# iostr735 register map
Registers are 16-bit, access not given, no defined reset value unless marked. A register's access mark holds for its fields unless they carry their own. Addresses are absolute; registers are grouped by the start of their names; [hi:lo] are bit positions; {n}, {i} and the like mark numbered series.

## GPIOPORT4
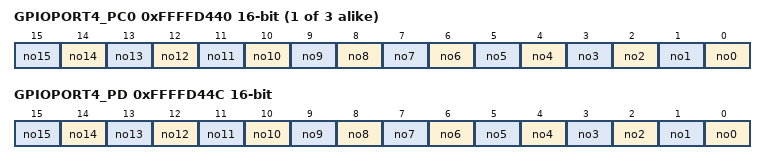
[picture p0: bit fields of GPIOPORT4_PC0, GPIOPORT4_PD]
{0xFFFFD440+4i} GPIOPORT4_PC{i} (i=0..2)
  [n] no{n} (n=0..15)
0xFFFFD44C GPIOPORT4_PD
  [n] no{n} (n=0..15)

## GPIOPORT5
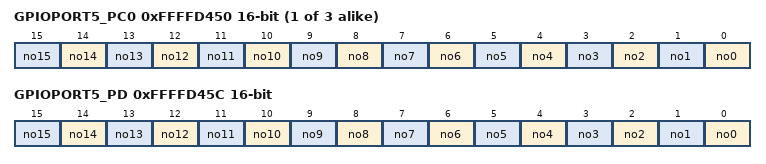
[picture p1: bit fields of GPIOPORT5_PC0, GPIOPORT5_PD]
{0xFFFFD450+4i} GPIOPORT5_PC{i} (i=0..2)
  [n] no{n} (n=0..15)
0xFFFFD45C GPIOPORT5_PD
  [n] no{n} (n=0..15)

## GPIOPORT6
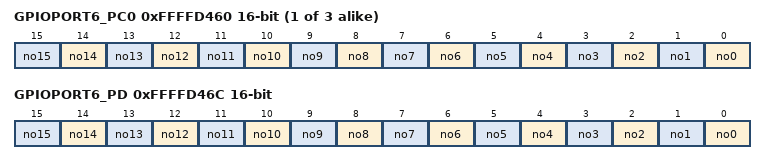
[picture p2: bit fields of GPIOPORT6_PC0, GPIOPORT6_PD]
{0xFFFFD460+4i} GPIOPORT6_PC{i} (i=0..2)
  [n] no{n} (n=0..15)
0xFFFFD46C GPIOPORT6_PD
  [n] no{n} (n=0..15)

## EIC
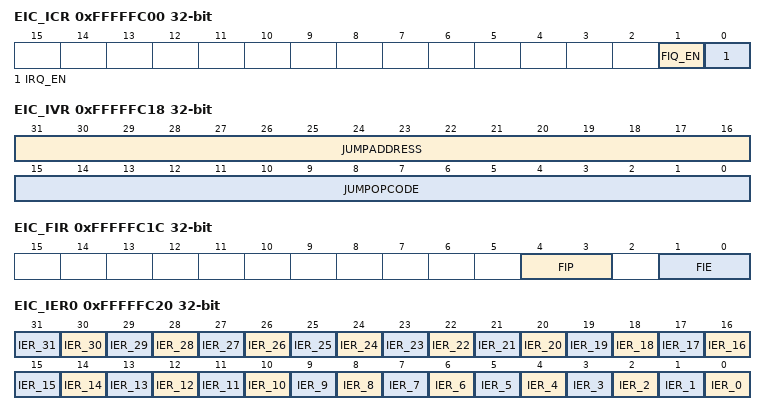
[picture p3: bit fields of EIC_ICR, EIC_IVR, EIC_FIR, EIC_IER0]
0xFFFFFC00 EIC_ICR 32-bit
  [1] FIQ_EN, [0] IRQ_EN
0xFFFFFC04 EIC_CICR 32-bit
  [5:0] CIC
0xFFFFFC08 EIC_CIPR 32-bit
  [3:0] CIP
0xFFFFFC10 EIC_FIER 32-bit
  [1:0] FIE
0xFFFFFC14 EIC_FIPR 32-bit
  [1:0] FIP
0xFFFFFC18 EIC_IVR 32-bit
  [31:16] JUMPADDRESS, [15:0] JUMPOPCODE
0xFFFFFC1C EIC_FIR 32-bit
  [4:3] FIP, [1:0] FIE
0xFFFFFC20 EIC_IER0 32-bit
  [n] IER_{n} (n=0..31)
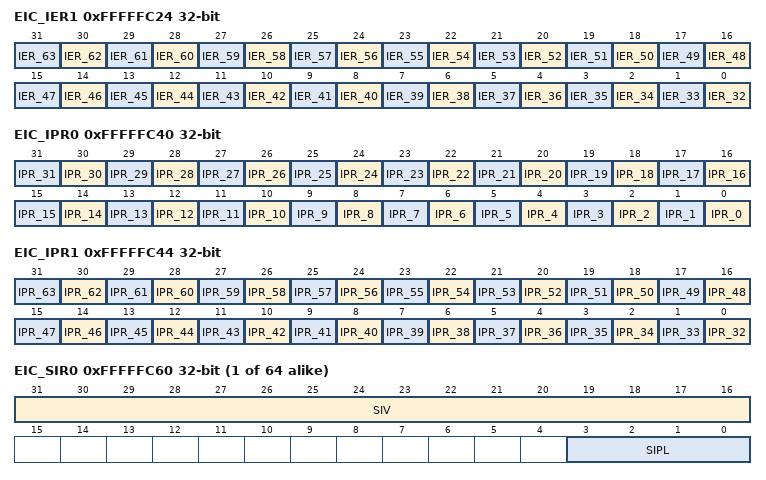
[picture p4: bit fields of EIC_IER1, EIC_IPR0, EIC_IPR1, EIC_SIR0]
0xFFFFFC24 EIC_IER1 32-bit
  [n-32] IER_{n} (n=32..63)
0xFFFFFC40 EIC_IPR0 32-bit
  [n] IPR_{n} (n=0..31)
0xFFFFFC44 EIC_IPR1 32-bit
  [n-32] IPR_{n} (n=32..63)
{0xFFFFFC60+4i} EIC_SIR{i} 32-bit (i=0..63)
  [31:16] SIV, [3:0] SIPL

## ARB
0x20000000 ARB_TOR 32-bit
  [15:0] TIMEOUT
0x20000004 ARB_PRIOR 32-bit
  [1:0] PRIORITY
0x2000000C ARB_CTRL 32-bit
  [1] ABORT

## FLASH
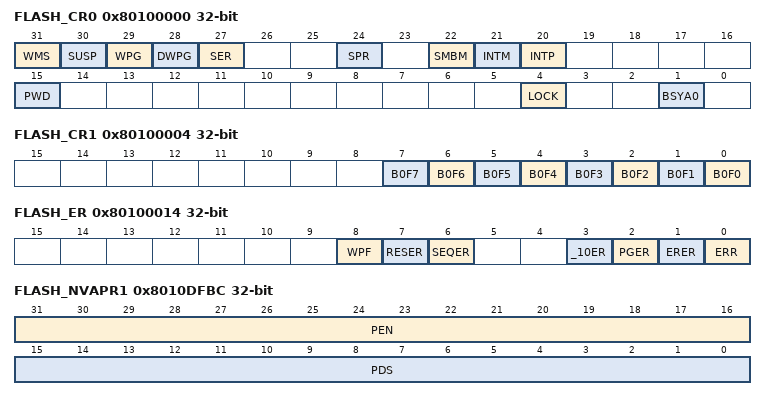
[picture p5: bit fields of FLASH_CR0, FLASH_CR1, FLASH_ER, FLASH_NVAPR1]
0x80100000 FLASH_CR0 32-bit
  [31] WMS, [30] SUSP, [29] WPG, [28] DWPG, [27] SER, [24] SPR, [22] SMBM, [21] INTM, [20] INTP, [15] PWD, [4] LOCK, [1] BSYA0
0x80100004 FLASH_CR1 32-bit
  [n] B0F{n} (n=0..7)
0x80100008 FLASH_DR0 32-bit
0x8010000C FLASH_DR1 32-bit
0x80100010 FLASH_AR 32-bit
  [20:0] ADD
0x80100014 FLASH_ER 32-bit
  [8] WPF, [7] RESER, [6] SEQER, [3] _10ER, [2] PGER, [1] ERER, [0] ERR
0x8010DFB0 FLASH_NVWPAR 32-bit
  [7:0] W0P
0x8010DFB8 FLASH_NVAPR0 32-bit
  [1] DBGP
0x8010DFBC FLASH_NVAPR1 32-bit
  [31:16] PEN, [15:0] PDS

## APB0
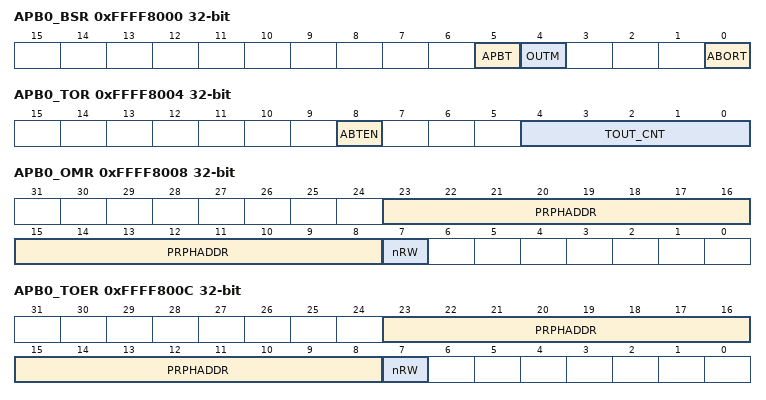
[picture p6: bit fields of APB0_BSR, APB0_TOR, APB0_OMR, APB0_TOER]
0xFFFF8000 APB0_BSR 32-bit
  [5] APBT, [4] OUTM, [0] ABORT
0xFFFF8004 APB0_TOR 32-bit
  [8] ABTEN, [4:0] TOUT_CNT
0xFFFF8008 APB0_OMR 32-bit
  [23:8] PRPHADDR, [7] nRW
0xFFFF800C APB0_TOER 32-bit
  [23:8] PRPHADDR, [7] nRW

## I2C0
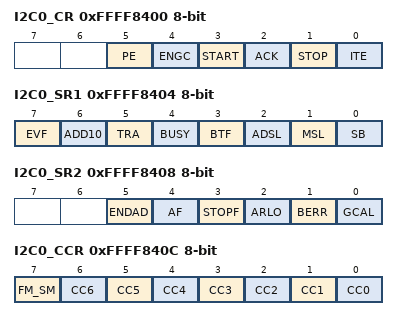
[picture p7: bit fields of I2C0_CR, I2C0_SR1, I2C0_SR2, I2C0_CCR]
0xFFFF8400 I2C0_CR 8-bit
  [5] PE, [4] ENGC, [3] START, [2] ACK, [1] STOP, [0] ITE
0xFFFF8404 I2C0_SR1 8-bit
  [7] EVF, [6] ADD10, [5] TRA, [4] BUSY, [3] BTF, [2] ADSL, [1] MSL, [0] SB
0xFFFF8408 I2C0_SR2 8-bit
  [5] ENDAD, [4] AF, [3] STOPF, [2] ARLO, [1] BERR, [0] GCAL
0xFFFF840C I2C0_CCR 8-bit
  [7] FM_SM, [n] CC{n} (n=0..6)
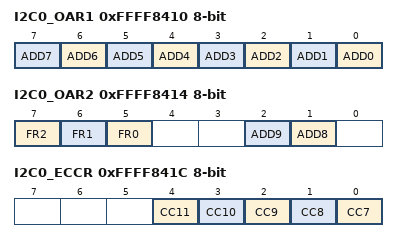
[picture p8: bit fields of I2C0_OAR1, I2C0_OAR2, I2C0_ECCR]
0xFFFF8410 I2C0_OAR1 8-bit
  [n] ADD{n} (n=0..7)
0xFFFF8414 I2C0_OAR2 8-bit
  [7] FR2, [6] FR1, [5] FR0, [2] ADD9, [1] ADD8
0xFFFF8418 I2C0_DR 8-bit
0xFFFF841C I2C0_ECCR 8-bit
  [n-7] CC{n} (n=7..11)

## I2C1
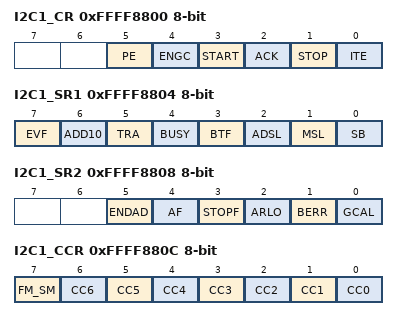
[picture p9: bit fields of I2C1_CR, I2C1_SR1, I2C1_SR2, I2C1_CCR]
0xFFFF8800 I2C1_CR 8-bit
  [5] PE, [4] ENGC, [3] START, [2] ACK, [1] STOP, [0] ITE
0xFFFF8804 I2C1_SR1 8-bit
  [7] EVF, [6] ADD10, [5] TRA, [4] BUSY, [3] BTF, [2] ADSL, [1] MSL, [0] SB
0xFFFF8808 I2C1_SR2 8-bit
  [5] ENDAD, [4] AF, [3] STOPF, [2] ARLO, [1] BERR, [0] GCAL
0xFFFF880C I2C1_CCR 8-bit
  [7] FM_SM, [n] CC{n} (n=0..6)
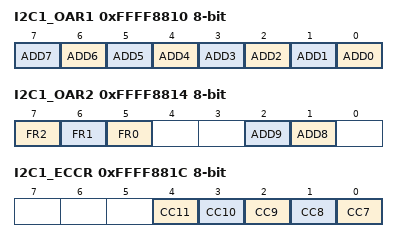
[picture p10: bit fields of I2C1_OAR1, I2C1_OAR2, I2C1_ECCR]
0xFFFF8810 I2C1_OAR1 8-bit
  [n] ADD{n} (n=0..7)
0xFFFF8814 I2C1_OAR2 8-bit
  [7] FR2, [6] FR1, [5] FR0, [2] ADD9, [1] ADD8
0xFFFF8818 I2C1_DR 8-bit
0xFFFF881C I2C1_ECCR 8-bit
  [n-7] CC{n} (n=7..11)

## TB0
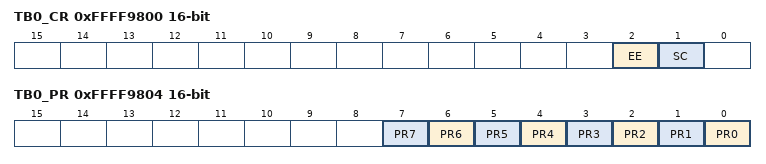
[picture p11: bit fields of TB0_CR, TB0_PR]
0xFFFF9800 TB0_CR
  [2] EE, [1] SC
0xFFFF9804 TB0_PR
  [n] PR{n} (n=0..7)
0xFFFF9808 TB0_VR
0xFFFF980C TB0_CNT
0xFFFF9810 TB0_SR
  [0] EC
0xFFFF9814 TB0_MR
  [0] ECM

## TB1
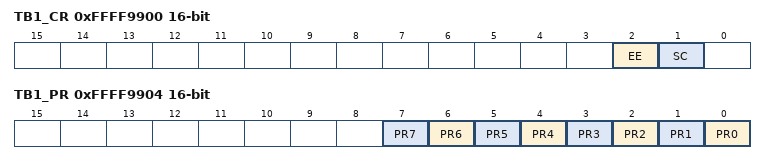
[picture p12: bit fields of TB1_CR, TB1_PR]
0xFFFF9900 TB1_CR
  [2] EE, [1] SC
0xFFFF9904 TB1_PR
  [n] PR{n} (n=0..7)
0xFFFF9908 TB1_VR
0xFFFF990C TB1_CNT
0xFFFF9910 TB1_SR
  [0] EC
0xFFFF9914 TB1_MR
  [0] ECM

## TB2
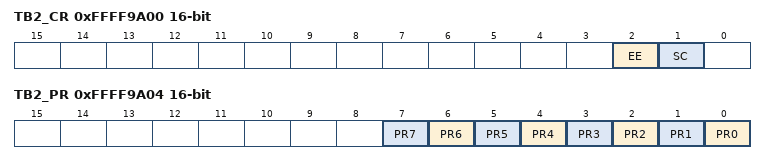
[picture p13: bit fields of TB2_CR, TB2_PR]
0xFFFF9A00 TB2_CR
  [2] EE, [1] SC
0xFFFF9A04 TB2_PR
  [n] PR{n} (n=0..7)
0xFFFF9A08 TB2_VR
0xFFFF9A0C TB2_CNT
0xFFFF9A10 TB2_SR
  [0] EC
0xFFFF9A14 TB2_MR
  [0] ECM
